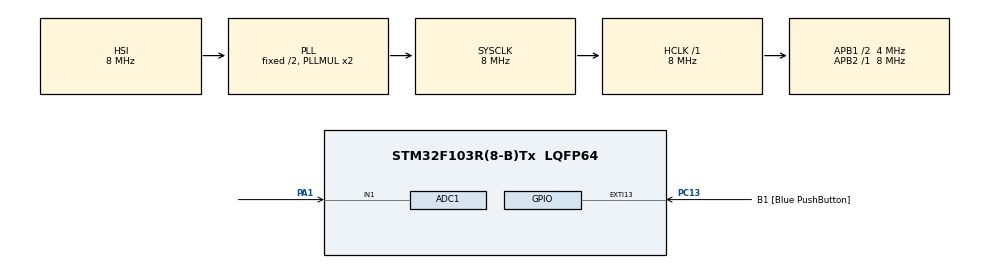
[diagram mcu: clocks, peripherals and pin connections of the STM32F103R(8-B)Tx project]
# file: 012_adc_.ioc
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ADC1.Channel-6\#ChannelRegularConversion=ADC_CHANNEL_1
ADC1.NbrOfConversionFlag=1
ADC1.Rank-6\#ChannelRegularConversion=1
ADC1.SamplingTime-6\#ChannelRegularConversion=ADC_SAMPLETIME_1CYCLE_5
ADC1.master=1
Mcu.Family=STM32F1
Mcu.Name=STM32F103R(8-B)Tx
Mcu.Package=LQFP64
NVIC.EXTI15_10_IRQn=true\:0\:0\:false\:false\:true\:true\:true\:true
NVIC.PriorityGroup=NVIC_PRIORITYGROUP_4
PA1.Signal=ADCx_IN1
PA13.GPIO_Label=TMS
PA13.Mode=Serial_Wire
PA13.Signal=SYS_JTMS-SWDIO
PA14.GPIO_Label=TCK
PA14.Mode=Serial_Wire
PA14.Signal=SYS_JTCK-SWCLK
PB3.GPIO_Label=SWO
PB3.Signal=SYS_JTDO-TRACESWO
PC13-TAMPER-RTC.GPIO_Label=B1 [Blue PushButton]
PC13-TAMPER-RTC.GPIO_PuPd=GPIO_NOPULL
PC13-TAMPER-RTC.Signal=GPXTI13
PC14-OSC32_IN.Mode=LSE-External-Oscillator
PC14-OSC32_IN.Signal=RCC_OSC32_IN
PC15-OSC32_OUT.Mode=LSE-External-Oscillator
PC15-OSC32_OUT.Signal=RCC_OSC32_OUT
PD0-OSC_IN.Mode=HSE-External-Clock-Source
PD0-OSC_IN.Signal=RCC_OSC_IN
PD1-OSC_OUT.Mode=HSE-External-Clock-Source
PD1-OSC_OUT.Signal=RCC_OSC_OUT
ProjectManager.HeapSize=0x200
ProjectManager.StackSize=0x400
ProjectManager.TargetToolchain=STM32CubeIDE
RCC.AHBFreq_Value=8000000
RCC.APB1CLKDivider=RCC_HCLK_DIV2
RCC.APB1Freq_Value=4000000
RCC.APB1TimFreq_Value=8000000
RCC.APB2Freq_Value=8000000
RCC.APB2TimFreq_Value=8000000
RCC.HCLKFreq_Value=8000000
RCC.RTCClockSelection=RCC_RTCCLKSOURCE_LSE
RCC.SYSCLKFreq_VALUE=8000000
RCC.SYSCLKSource=RCC_SYSCLKSOURCE_PLLCLK
RCC.USBFreq_Value=8000000
SH.ADCx_IN1.0=ADC1_IN1,IN1
board=NUCLEO-F103RB

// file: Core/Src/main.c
/* USER CODE BEGIN Header */
/**
  ******************************************************************************
  * @file           : main.c
  * @brief          : Main program body
  ******************************************************************************
  * @attention
  *
  * Copyright (c) 2025 STMicroelectronics.
  * All rights reserved.
  *
  * This software is licensed under terms that can be found in the LICENSE file
  * in the root directory of this software component.
  * If no LICENSE file comes with this software, it is provided AS-IS.
  *
  ******************************************************************************
  */
/* USER CODE END Header */
#include "main.h"

ADC_HandleTypeDef hadc1;

#define VREF 3.3f               // Reference voltage for ADC
#define ADC_RESOLUTION 4096.0f  // 12-bit ADC resolution
#define TEMP_MIN 0.0f           // Minimum temperature (e.g., 0°C)
#define TEMP_MAX 100.0f         // Maximum temperature (e.g., 100°C)
#define CURRENT_MIN 4.0f        // Minimum current (4mA)
#define CURRENT_MAX 20.0f       // Maximum current (20mA)
#define VOLTAGE_MIN 1.0f        // Voltage corresponding to 4mA
#define VOLTAGE_MAX 5.0f        // Voltage corresponding to 20mA

/* USER CODE BEGIN 0 */
void SystemClock_Config(void);
static void MX_GPIO_Init(void);
static void MX_ADC1_Init(void);

/* USER CODE END 0 */

float readTemperature(void) {
    uint32_t adc_value;

    // Start ADC conversion
    HAL_ADC_Start(&hadc1);

    // Poll for conversion completion
    if (HAL_ADC_PollForConversion(&hadc1, HAL_MAX_DELAY) == HAL_OK) {
        // Get ADC value
        adc_value = HAL_ADC_GetValue(&hadc1);
    }

    // Stop ADC
    HAL_ADC_Stop(&hadc1);

    // Convert ADC value to voltage
    float voltage = (float)adc_value * (VREF / ADC_RESOLUTION);

    // Map voltage to temperature
    float current = (voltage - VOLTAGE_MIN) * ((CURRENT_MAX - CURRENT_MIN) / (VOLTAGE_MAX - VOLTAGE_MIN)) + CURRENT_MIN;
    float temperature = (current - CURRENT_MIN) * ((TEMP_MAX - TEMP_MIN) / (CURRENT_MAX - CURRENT_MIN)) + TEMP_MIN;

    return temperature;
}

int main(void) {
    // HAL Initialization
	HAL_Init();

	  /* Configure the system clock */
	  SystemClock_Config();

	  /* Initialize all configured peripherals */
	  //MX_GPIO_Init();
	  MX_ADC1_Init();
	  //MX_I2C2_Init();
	  /* USER CODE BEGIN 2 */
	  HAL_ADC_Start (&hadc1);

    while (1) {
        // Read temperature
        float temperature = readTemperature();

        // Print temperature (use UART for debugging)
        printf("Temperature: %.2f °C\n", temperature);

        // Delay
        HAL_Delay(1000);
    }
}

void SystemClock_Config(void)
{
  RCC_OscInitTypeDef RCC_OscInitStruct = {0};
  RCC_ClkInitTypeDef RCC_ClkInitStruct = {0};
  RCC_PeriphCLKInitTypeDef PeriphClkInit = {0};

  /** Initializes the RCC Oscillators according to the specified parameters
  * in the RCC_OscInitTypeDef structure.
  */
  RCC_OscInitStruct.OscillatorType = RCC_OSCILLATORTYPE_HSI;
  RCC_OscInitStruct.HSIState = RCC_HSI_ON;
  RCC_OscInitStruct.HSICalibrationValue = RCC_HSICALIBRATION_DEFAULT;
  RCC_OscInitStruct.PLL.PLLState = RCC_PLL_ON;
  RCC_OscInitStruct.PLL.PLLSource = RCC_PLLSOURCE_HSI_DIV2;
  RCC_OscInitStruct.PLL.PLLMUL = RCC_PLL_MUL2;
  if (HAL_RCC_OscConfig(&RCC_OscInitStruct) != HAL_OK)
  {
    Error_Handler();
  }

  /** Initializes the CPU, AHB and APB buses clocks
  */
  RCC_ClkInitStruct.ClockType = RCC_CLOCKTYPE_HCLK|RCC_CLOCKTYPE_SYSCLK
                              |RCC_CLOCKTYPE_PCLK1|RCC_CLOCKTYPE_PCLK2;
  RCC_ClkInitStruct.SYSCLKSource = RCC_SYSCLKSOURCE_PLLCLK;
  RCC_ClkInitStruct.AHBCLKDivider = RCC_SYSCLK_DIV1;
  RCC_ClkInitStruct.APB1CLKDivider = RCC_HCLK_DIV2;
  RCC_ClkInitStruct.APB2CLKDivider = RCC_HCLK_DIV1;

  if (HAL_RCC_ClockConfig(&RCC_ClkInitStruct, FLASH_LATENCY_0) != HAL_OK)
  {
    Error_Handler();
  }
  PeriphClkInit.PeriphClockSelection = RCC_PERIPHCLK_ADC;
  PeriphClkInit.AdcClockSelection = RCC_ADCPCLK2_DIV2;
  if (HAL_RCCEx_PeriphCLKConfig(&PeriphClkInit) != HAL_OK)
  {
    Error_Handler();
  }
}

static void MX_ADC1_Init(void)
{

  ADC_ChannelConfTypeDef sConfig = {0};

  /** Common config
  */
  hadc1.Instance = ADC1;
  hadc1.Init.ScanConvMode = ADC_SCAN_ENABLE;
  hadc1.Init.ContinuousConvMode = ENABLE;
  hadc1.Init.DiscontinuousConvMode = DISABLE;
  hadc1.Init.ExternalTrigConv = ADC_SOFTWARE_START;
  hadc1.Init.DataAlign = ADC_DATAALIGN_RIGHT;
  hadc1.Init.NbrOfConversion = 1;
  if (HAL_ADC_Init(&hadc1) != HAL_OK)
  {
    Error_Handler();
  }

  /** Configure Regular Channel
  */
  sConfig.Channel = ADC_CHANNEL_1;
  sConfig.Rank = ADC_REGULAR_RANK_1;
  sConfig.SamplingTime = ADC_SAMPLETIME_1CYCLE_5;
  if (HAL_ADC_ConfigChannel(&hadc1, &sConfig) != HAL_OK)
  {
    Error_Handler();
  }

}

static void MX_GPIO_Init(void)
{
  GPIO_InitTypeDef GPIO_InitStruct = {0};

  /* GPIO Ports Clock Enable */
  __HAL_RCC_GPIOC_CLK_ENABLE();
  __HAL_RCC_GPIOD_CLK_ENABLE();
  __HAL_RCC_GPIOA_CLK_ENABLE();
  __HAL_RCC_GPIOB_CLK_ENABLE();

  /*Configure GPIO pin : B1_Pin */
  GPIO_InitStruct.Pin = B1_Pin;
  GPIO_InitStruct.Mode = GPIO_MODE_IT_RISING;
  GPIO_InitStruct.Pull = GPIO_NOPULL;
  HAL_GPIO_Init(B1_GPIO_Port, &GPIO_InitStruct);

  /* EXTI interrupt init*/
  HAL_NVIC_SetPriority(EXTI15_10_IRQn, 0, 0);
  HAL_NVIC_EnableIRQ(EXTI15_10_IRQn);

}

void Error_Handler(void)
{
  __disable_irq();
  while (1)
  {
  }
}
